# ESP32-C3 register map
Vendor: ESPRESSIF SYSTEMS (SHANGHAI) CO., LTD.; Series: ESP32-C3; File version: 8
CPU: RV32IMC r0p0, little endian, no MPU, no FPU, 4 interrupt priority bits
Address unit: 32 bits
Registers are 32-bit, read-write, reset 0x0 unless marked. A register's access mark holds for its fields unless they carry their own. Offsets are from the block's base; [hi:lo] are bit positions; {n}, {i} and the like mark numbered series.

## IO_MUX — Input/Output Multiplexer
Base 0x60009000
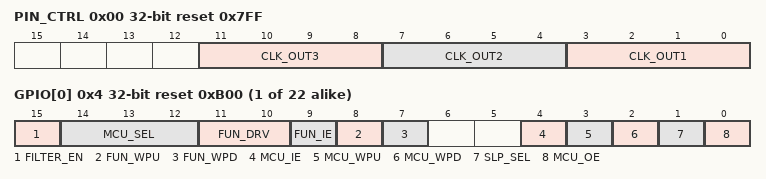
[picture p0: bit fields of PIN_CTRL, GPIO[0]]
0x00 PIN_CTRL reset 0x7FF — Clock Output Configuration Register
  [11:8] CLK_OUT3 — If you want to output clock for I2S to CLK_OUT_out3, set this register to 0x0. CLK_OUT_out3 can be found in peripheral output signals.
  [7:4] CLK_OUT2 — If you want to output clock for I2S to CLK_OUT_out2, set this register to 0x0. CLK_OUT_out2 can be found in peripheral output signals.
  [3:0] CLK_OUT1 — If you want to output clock for I2S to CLK_OUT_out1, set this register to 0x0. CLK_OUT_out1 can be found in peripheral output signals.
{0x4+4i} GPIO[{i}] (i=0..21) reset 0xB00 — IO MUX Configure Register for pad XTAL_32K_P
  [15] FILTER_EN — Enable filter for pin input signals. 1: Filter enabled; 2: Filter disabled.
  [14:12] MCU_SEL — Select IO MUX function for this signal. 0: Select Function 1; 1: Select Function 2; etc.
  [11:10] FUN_DRV — Select the drive strength of the pad. 0: ~5 mA; 1: ~10mA; 2: ~20mA; 3: ~40mA.
  [9] FUN_IE — Input enable of the pad. 1: input enabled; 0: input disabled.
  [8] FUN_WPU — Pull-up enable of the pad. 1: internal pull-up enabled; 0: internal pull-up disabled.
  [7] FUN_WPD — Pull-down enable of the pad. 1: internal pull-down enabled; 0: internal pull-down disabled.
  [4] MCU_IE — Input enable of the pad during sleep mode. 1: input enabled; 0: input disabled.
  [3] MCU_WPU — Pull-up enable of the pad during sleep mode. 1: internal pull-up enabled; 0: internal pull-up disabled.
  [2] MCU_WPD — Pull-down enable of the pad in sleep mode. 1: internal pull-down enabled; 0: internal pull-down disabled.
  [1] SLP_SEL — Sleep mode selection of this pad. Set to 1 to put the pad in pad mode.
  [0] MCU_OE — Output enable of the pad in sleep mode. 1: output enabled; 0: output disabled.
0xFC DATE reset 0x2006050 — IO MUX Version Control Register
  [27:0] REG_DATE — Version control register

## LEDC — LED Control PWM (Pulse Width Modulation)
Base 0x60019000
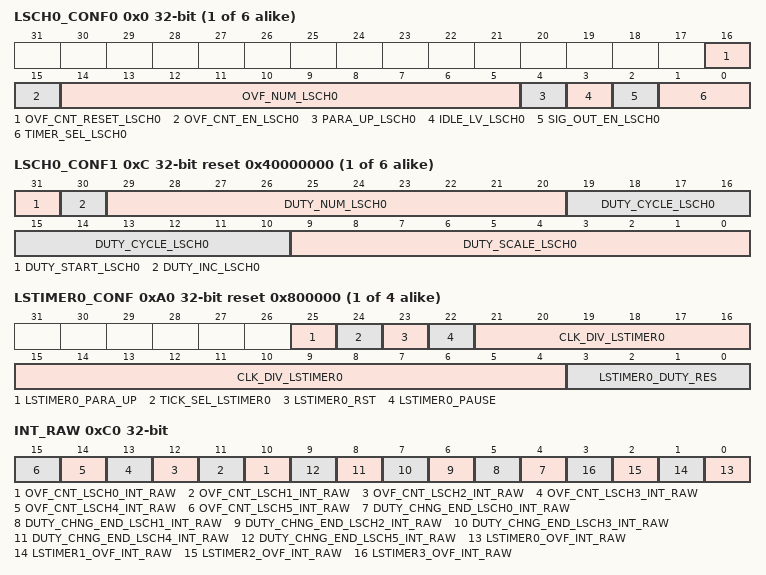
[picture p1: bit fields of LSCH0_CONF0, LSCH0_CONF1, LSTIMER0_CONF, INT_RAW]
{0x0+0x14*i} LSCH{i}_CONF0 access per field (i=0..5) — LEDC_LSCH{i}_CONF0.
  [16] OVF_CNT_RESET_LSCH{i} wo — reg_ovf_cnt_reset_lsch{i}.
  [15] OVF_CNT_EN_LSCH{i} rw — reg_ovf_cnt_en_lsch{i}.
  [14:5] OVF_NUM_LSCH{i} rw — reg_ovf_num_lsch{i}.
  [4] PARA_UP_LSCH{i} wo — reg_para_up_lsch{i}.
  [3] IDLE_LV_LSCH{i} rw — reg_idle_lv_lsch{i}.
  [2] SIG_OUT_EN_LSCH{i} rw — reg_sig_out_en_lsch{i}.
  [1:0] TIMER_SEL_LSCH{i} rw — reg_timer_sel_lsch{i}.
{0x4+0x14*i} LSCH{i}_HPOINT (i=0..5) — LEDC_LSCH{i}_HPOINT.
  [13:0] HPOINT_LSCH{i} — reg_hpoint_lsch{i}.
{0x8+0x14*i} LSCH{i}_DUTY (i=0..5) — LEDC_LSCH{i}_DUTY.
  [18:0] DUTY_LSCH{i} — reg_duty_lsch{i}.
{0xC+0x14*i} LSCH{i}_CONF1 reset 0x40000000 (i=0..5) — LEDC_LSCH{i}_CONF1.
  [31] DUTY_START_LSCH{i} — reg_duty_start_lsch{i}.
  [30] DUTY_INC_LSCH{i} — reg_duty_inc_lsch{i}.
  [29:20] DUTY_NUM_LSCH{i} — reg_duty_num_lsch{i}.
  [19:10] DUTY_CYCLE_LSCH{i} — reg_duty_cycle_lsch{i}.
  [9:0] DUTY_SCALE_LSCH{i} — reg_duty_scale_lsch{i}.
{0x10+0x14*i} LSCH{i}_DUTY_R ro (i=0..5) — LEDC_LSCH{i}_DUTY_R.
  [18:0] DUTY_LSCH{i}_R — reg_duty_lsch{i}_r.
{0xA0+8i} LSTIMER{i}_CONF access per field reset 0x800000 (i=0..3) — LEDC_LSTIMER{i}_CONF.
  [25] LSTIMER{i}_PARA_UP wo — reg_lstimer{i}_para_up.
  [24] TICK_SEL_LSTIMER{i} rw — reg_tick_sel_lstimer{i}.
  [23] LSTIMER{i}_RST rw — reg_lstimer{i}_rst.
  [22] LSTIMER{i}_PAUSE rw — reg_lstimer{i}_pause.
  [21:4] CLK_DIV_LSTIMER{i} rw — reg_clk_div_lstimer{i}.
  [3:0] LSTIMER{i}_DUTY_RES rw — reg_lstimer{i}_duty_res.
{0xA4+8i} LSTIMER{i}_VALUE ro (i=0..3) — LEDC_LSTIMER{i}_VALUE.
  [13:0] LSTIMER{i}_CNT — reg_lstimer{i}_cnt.
0xC0 INT_RAW ro — LEDC_INT_RAW.
  [n+10] OVF_CNT_LSCH{n}_INT_RAW (n=0..5) — reg_ovf_cnt_lsch{n}_int_raw.
  [n+4] DUTY_CHNG_END_LSCH{n}_INT_RAW (n=0..5) — reg_duty_chng_end_lsch{n}_int_raw.
  [n] LSTIMER{n}_OVF_INT_RAW (n=0..3) — reg_lstimer{n}_ovf_int_raw.
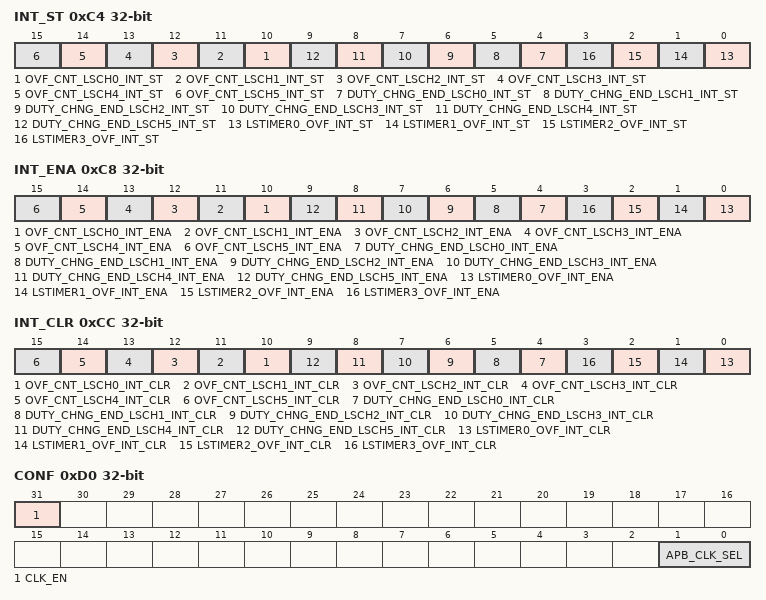
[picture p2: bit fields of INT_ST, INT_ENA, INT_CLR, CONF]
0xC4 INT_ST ro — LEDC_INT_ST.
  [n+10] OVF_CNT_LSCH{n}_INT_ST (n=0..5) — reg_ovf_cnt_lsch{n}_int_st.
  [n+4] DUTY_CHNG_END_LSCH{n}_INT_ST (n=0..5) — reg_duty_chng_end_lsch{n}_int_st.
  [n] LSTIMER{n}_OVF_INT_ST (n=0..3) — reg_lstimer{n}_ovf_int_st.
0xC8 INT_ENA — LEDC_INT_ENA.
  [n+10] OVF_CNT_LSCH{n}_INT_ENA (n=0..5) — reg_ovf_cnt_lsch{n}_int_ena.
  [n+4] DUTY_CHNG_END_LSCH{n}_INT_ENA (n=0..5) — reg_duty_chng_end_lsch{n}_int_ena.
  [n] LSTIMER{n}_OVF_INT_ENA (n=0..3) — reg_lstimer{n}_ovf_int_ena.
0xCC INT_CLR wo — LEDC_INT_CLR.
  [n+10] OVF_CNT_LSCH{n}_INT_CLR (n=0..5) — reg_ovf_cnt_lsch{n}_int_clr.
  [n+4] DUTY_CHNG_END_LSCH{n}_INT_CLR (n=0..5) — reg_duty_chng_end_lsch{n}_int_clr.
  [n] LSTIMER{n}_OVF_INT_CLR (n=0..3) — reg_lstimer{n}_ovf_int_clr.
0xD0 CONF — LEDC_CONF.
  [31] CLK_EN — reg_clk_en.
  [1:0] APB_CLK_SEL — reg_apb_clk_sel.
0xFC DATE reset 0x19061700 — LEDC_DATE.
  [31:0] LEDC_DATE — reg_ledc_date.
